VERSION ""

NS_ :

BS_:

BU_: IMU
VAL_TABLE_ satellite_state_values 9 "RTK浮点解定位 不定向" 8 "RTK稳定解定位 不定向" 7 "伪距差分定位不 定向" 6 "单点定位不定向" 5 "RTK浮点解定位 定向" 4 "RTK稳定解定位 定向" 3 "组合推算" 2 "伪距差分定位定向" 1 "单天线定位定向" 0 "不定位不定向" ;
VAL_TABLE_ system_state_values 3 "Inertial navigation mode" 2 "Integrated navigation mode" 1 "Satellite navigation mode" 0 "Initing" ;

BO_ 814 Latitude: 8 Vector__XXX
 SG_ PosLat2 : 7|64@0- (1E-008,0) [-90|90] "deg" Vector__XXX

BO_ 813 Longitude: 8 Vector__XXX
 SG_ PosLon2 : 7|64@0- (1E-008,0) [-180|180] "deg" Vector__XXX

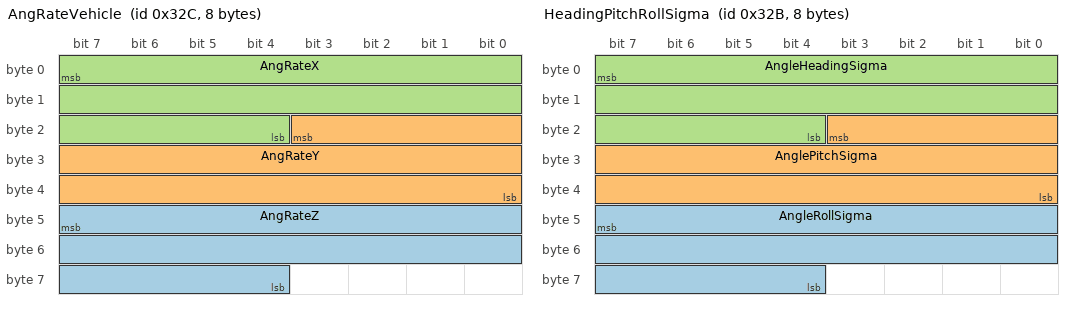
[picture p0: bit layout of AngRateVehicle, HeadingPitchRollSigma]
BO_ 812 AngRateVehicle: 8 IMU
 SG_ AngRateZ : 47|20@0- (0.01,0) [-500|500] "deg/s" Vector__XXX
 SG_ AngRateY : 19|20@0- (0.01,0) [-500|500] "deg/s" Vector__XXX
 SG_ AngRateX : 7|20@0- (0.01,0) [-500|500] "deg/s" Vector__XXX

BO_ 811 HeadingPitchRollSigma: 8 IMU
 SG_ AngleRollSigma : 47|20@0+ (0.0001,0) [0|100] "deg" Vector__XXX
 SG_ AnglePitchSigma : 19|20@0+ (0.0001,0) [0|100] "deg" Vector__XXX
 SG_ AngleHeadingSigma : 7|20@0+ (0.0001,0) [0|100] "deg" Vector__XXX

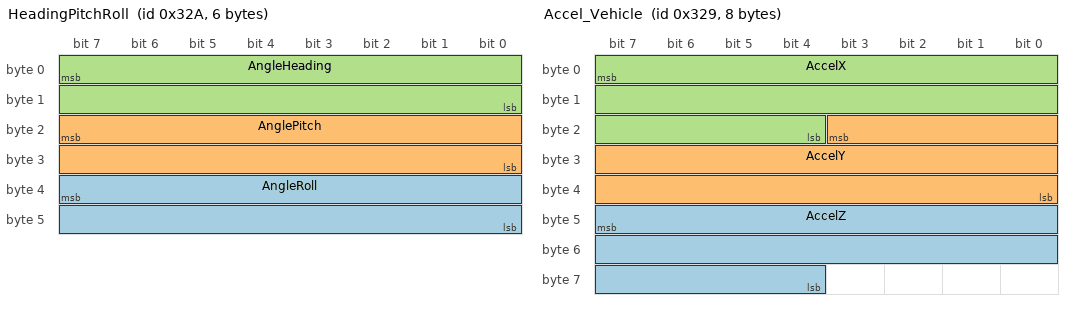
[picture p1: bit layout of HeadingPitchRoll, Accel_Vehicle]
BO_ 810 HeadingPitchRoll: 6 IMU
 SG_ AngleRoll : 39|16@0- (0.01,0) [-180|180] "deg" Vector__XXX
 SG_ AnglePitch : 23|16@0- (0.01,0) [-90|90] "deg" Vector__XXX
 SG_ AngleHeading : 7|16@0+ (0.01,0) [0|360] "deg" Vector__XXX

BO_ 809 Accel_Vehicle: 8 IMU
 SG_ AccelZ : 47|20@0- (0.0001,0) [-8|8] "g" Vector__XXX
 SG_ AccelY : 19|20@0- (0.0001,0) [-8|8] "g" Vector__XXX
 SG_ AccelX : 7|20@0- (0.0001,0) [-8|8] "g" Vector__XXX

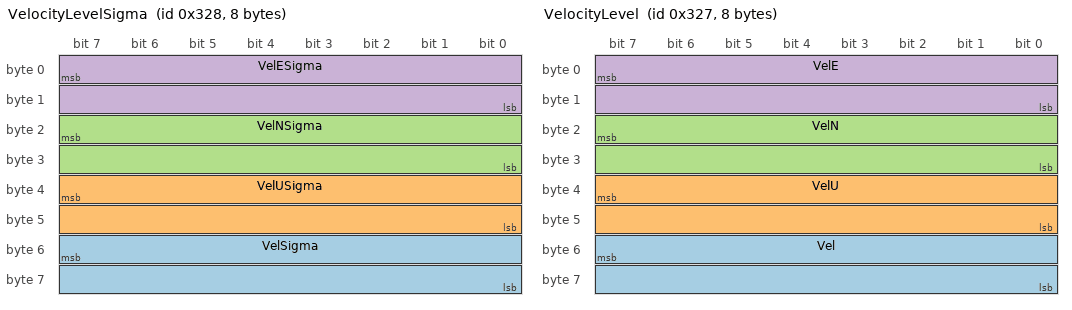
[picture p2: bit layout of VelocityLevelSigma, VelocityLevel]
BO_ 808 VelocityLevelSigma: 8 IMU
 SG_ VelSigma : 55|16@0+ (0.001,0) [0|65.535] "m/s" Vector__XXX
 SG_ VelUSigma : 39|16@0+ (0.001,0) [0|65.535] "m/s" Vector__XXX
 SG_ VelNSigma : 23|16@0+ (0.001,0) [0|65.535] "m/s" Vector__XXX
 SG_ VelESigma : 7|16@0+ (0.001,0) [0|65.535] "m/s" Vector__XXX

BO_ 800 Time: 6 IMU
 SG_ GpsTime : 23|32@0+ (0.001,0) [0|4294967.295] "s" Vector__XXX
 SG_ GpsWeek : 7|16@0+ (1,0) [0|65535] "w" Vector__XXX

BO_ 807 VelocityLevel: 8 IMU
 SG_ Vel : 55|16@0- (0.01,0) [-327.68|327.67] "m/s" Vector__XXX
 SG_ VelU : 39|16@0- (0.01,0) [-327.68|327.67] "m/s" Vector__XXX
 SG_ VelN : 23|16@0- (0.01,0) [-327.68|327.67] "m/s" Vector__XXX
 SG_ VelE : 7|16@0- (0.01,0) [-327.68|327.67] "m/s" Vector__XXX

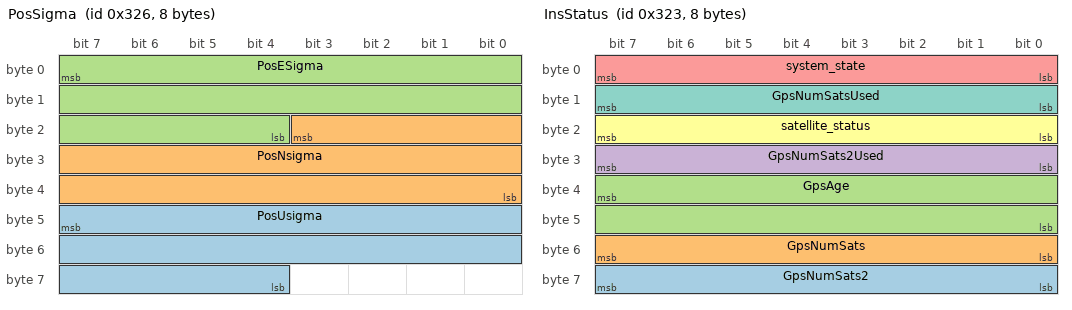
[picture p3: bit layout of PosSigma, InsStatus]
BO_ 806 PosSigma: 8 IMU
 SG_ PosUsigma : 47|20@0+ (0.0001,0) [0|100] "m" Vector__XXX
 SG_ PosNsigma : 19|20@0+ (0.0001,0) [0|100] "m" Vector__XXX
 SG_ PosESigma : 7|20@0+ (0.0001,0) [0|100] "m" Vector__XXX

BO_ 805 Altitude: 4 IMU
 SG_ PosAlt : 7|32@0- (0.001,0) [-2147483.648|2147483.648] "m" Vector__XXX

BO_ 804 LatitudeLongitude: 8 IMU
 SG_ PosLon : 39|32@0- (1E-007,0) [-214.7483648|214.7483648] "deg" Vector__XXX
 SG_ PosLat : 7|32@0- (1E-007,0) [-214.7483648|214.7483648] "deg" Vector__XXX

BO_ 803 InsStatus: 8 IMU
 SG_ GpsNumSats2 : 63|8@0+ (1,0) [0|255] "" Vector__XXX
 SG_ GpsNumSats : 55|8@0+ (1,0) [0|255] "" Vector__XXX
 SG_ GpsAge : 39|16@0+ (0.01,0) [0|655.35] "" Vector__XXX
 SG_ GpsNumSats2Used : 31|8@0+ (1,0) [0|255] "" Vector__XXX
 SG_ system_state : 7|8@0+ (1,0) [0|9] "" Vector__XXX
 SG_ satellite_status : 23|8@0+ (1,0) [0|9] "" Vector__XXX
 SG_ GpsNumSatsUsed : 15|8@0+ (1,0) [0|255] "" Vector__XXX

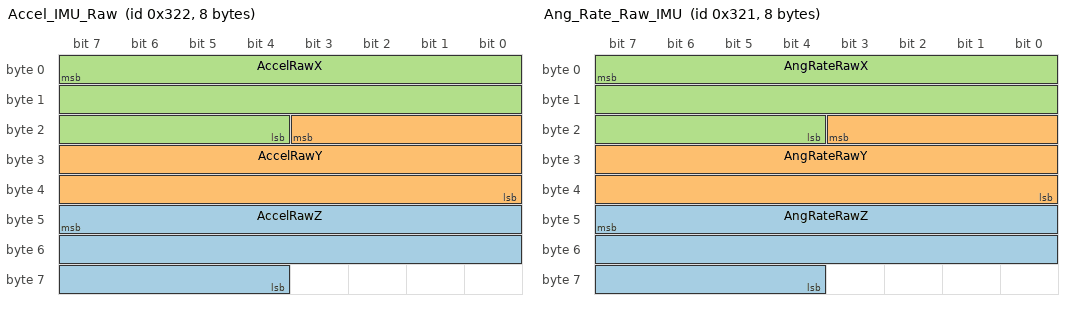
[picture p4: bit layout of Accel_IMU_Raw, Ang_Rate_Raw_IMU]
BO_ 802 Accel_IMU_Raw: 8 IMU
 SG_ AccelRawZ : 47|20@0- (0.0001,0) [-50|50] "g" Vector__XXX
 SG_ AccelRawY : 19|20@0- (0.0001,0) [-50|50] "g" Vector__XXX
 SG_ AccelRawX : 7|20@0- (0.0001,0) [-50|50] "g" Vector__XXX

BO_ 801 Ang_Rate_Raw_IMU: 8 IMU
 SG_ AngRateRawZ : 47|20@0- (0.01,0) [-500|500] "deg/s" Vector__XXX
 SG_ AngRateRawY : 19|20@0- (0.01,0) [-500|500] "deg/s" Vector__XXX
 SG_ AngRateRawX : 7|20@0- (0.01,0) [-500|500] "deg/s" Vector__XXX

CM_ SG_ 800 GpsTime "The number of seconds since 0:00:00 GMT this Sunday";
CM_ SG_ 800 GpsWeek "Number of weeks from 1980-1-6 to the present (Grinidge Time)";
CM_ SG_ 803 GpsNumSats2 "Number of satellites searched by auxiliary antenna";
CM_ SG_ 803 GpsNumSats "Number of satellites searched by the main antenna";
CM_ SG_ 803 GpsAge "Differential delay";
CM_ SG_ 803 GpsNumSats2Used "The number of satellites used by the auxiliary antenna";
CM_ SG_ 803 system_state "RTK system working state";
CM_ SG_ 803 satellite_status "statellite working state";
CM_ SG_ 803 GpsNumSatsUsed "Number of main antenna satellites used";
BA_DEF_ SG_  "GenSigSendType" ENUM  "Cyclic","OnWrite","OnWriteWithRepetition","OnChange","OnChangeWithRepetition","IfActive","IfActiveWithRepetition","NoSigSendType";
BA_DEF_ BO_  "GenMsgSendType" ENUM  "Cyclic","not_used","not_used","not_used","not_used","Cyclic","not_used","IfActive","NoMsgSendType";
BA_DEF_  "DBName" STRING ;
BA_DEF_  "BusType" STRING ;
BA_DEF_DEF_  "GenSigSendType" "Cyclic";
BA_DEF_DEF_  "GenMsgSendType" "NoMsgSendType";
BA_DEF_DEF_  "DBName" "";
BA_DEF_DEF_  "BusType" "CAN";
BA_ "DBName" "CANProtocol";
VAL_ 803 system_state 3 "Inertial navigation mode" 2 "Integrated navigation mode" 1 "Satellite navigation mode" 0 "Initing" ;
VAL_ 803 satellite_status 9 "RTK浮点解定位 不定向" 8 "RTK稳定解定位 不定向" 7 "伪距差分定位不 定向" 6 "单点定位不定向" 5 "RTK浮点解定位 定向" 4 "RTK稳定解定位 定向" 3 "组合推算" 2 "伪距差分定位定向" 1 "单天线定位定向" 0 "不定位不定向" ;
